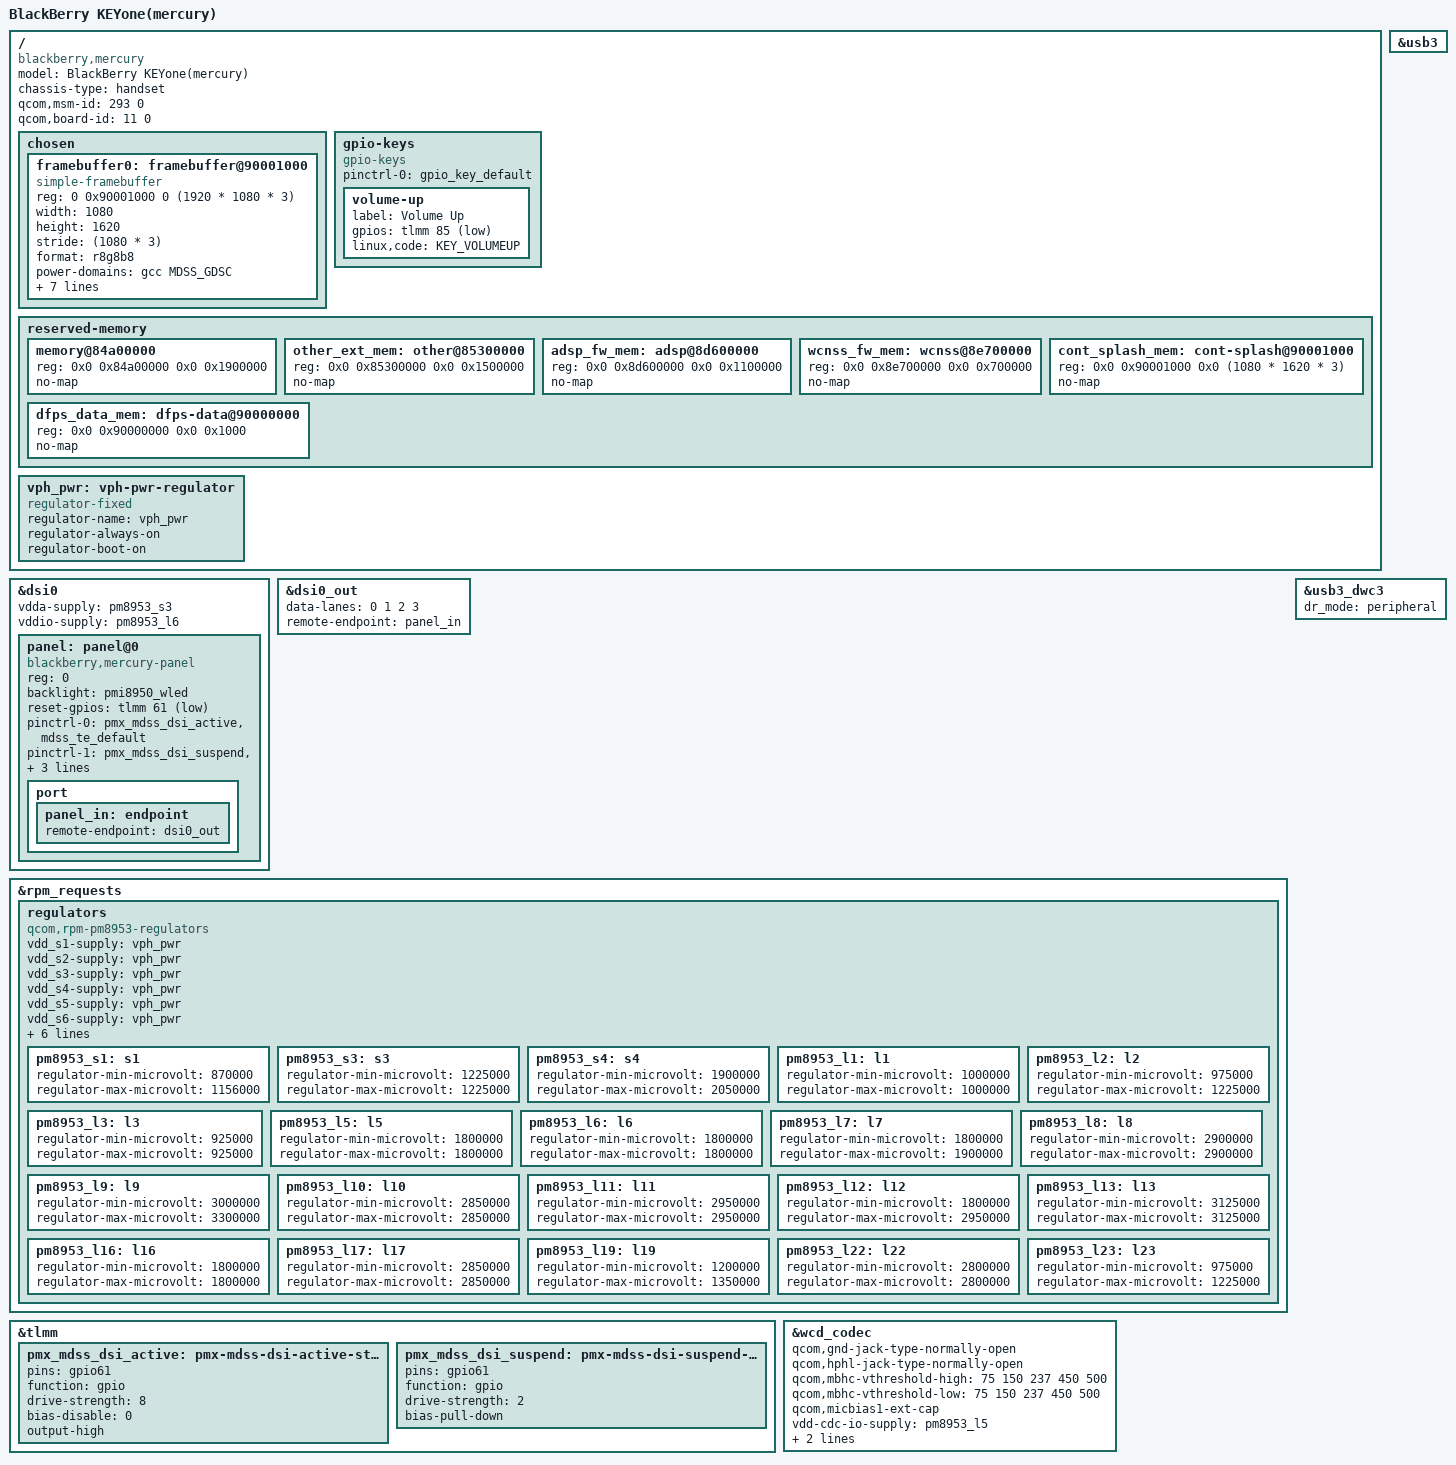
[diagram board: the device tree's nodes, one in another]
// SPDX-License-Identifier: GPL-2.0-only
/dts-v1/;

#include "msm8953.dtsi"
#include "pm8953.dtsi"
#include "pmi8950.dtsi"

#include <dt-bindings/gpio/gpio.h>
#include <dt-bindings/leds/common.h>

/delete-node/ &adsp_fw_mem;
/delete-node/ &wcnss_fw_mem;

/ {
	model = "BlackBerry KEYone(mercury)";
	compatible = "blackberry,mercury", "qcom,msm8953";
	chassis-type = "handset";
	qcom,msm-id = <293 0>;
	qcom,board-id = <11 0>;

	chosen {
		#address-cells = <2>;
		#size-cells = <2>;
		ranges;

		framebuffer0: framebuffer@90001000 {
			compatible = "simple-framebuffer";
			reg = <0 0x90001000 0 (1920 * 1080 * 3)>;

			width = <1080>;
			height = <1620>;
			stride = <(1080 * 3)>;
			format = "r8g8b8";

			power-domains = <&gcc MDSS_GDSC>;

			clocks = <&gcc GCC_MDSS_AHB_CLK>,
				 <&gcc GCC_MDSS_AXI_CLK>,
				 <&gcc GCC_MDSS_VSYNC_CLK>,
				 <&gcc GCC_MDSS_MDP_CLK>,
				 <&gcc GCC_MDSS_BYTE0_CLK>,
				 <&gcc GCC_MDSS_PCLK0_CLK>,
				 <&gcc GCC_MDSS_ESC0_CLK>;
		};
	};

	gpio-keys {
		compatible = "gpio-keys";

		pinctrl-names = "default";
		pinctrl-0 = <&gpio_key_default>;

		volume-up {
			label = "Volume Up";
			gpios = <&tlmm 85 GPIO_ACTIVE_LOW>;
			linux,code = <KEY_VOLUMEUP>;
		};
	};

	reserved-memory {
		/delete-node/memory@85b00000;

		memory@84a00000 {
			reg = <0x0 0x84a00000 0x0 0x1900000>;
			no-map;
		};

		other_ext_mem: other@85300000 {
                        reg = <0x0 0x85300000 0x0 0x1500000>;
			no-map;
                };

		adsp_fw_mem: adsp@8d600000 {
                        reg = <0x0 0x8d600000 0x0 0x1100000>;
                        no-map;
                };

		wcnss_fw_mem: wcnss@8e700000 {
                        reg = <0x0 0x8e700000 0x0 0x700000>;
                        no-map;
                };

		/delete-node/memory@90001000;
		cont_splash_mem: cont-splash@90001000 {
			reg = <0x0 0x90001000 0x0 (1080 * 1620 * 3)>;
			no-map;
		};

		dfps_data_mem: dfps-data@90000000 {
                        reg = <0x0 0x90000000 0x0 0x1000>;
			no-map;
                };

	};

	vph_pwr: vph-pwr-regulator {
		compatible = "regulator-fixed";
		regulator-name = "vph_pwr";
		regulator-always-on;
		regulator-boot-on;
	};

};

&dsi0 {
	vdda-supply = <&pm8953_s3>;
	vddio-supply = <&pm8953_l6>;

	panel: panel@0 {
		compatible = "blackberry,mercury-panel";
		reg = <0>;

		backlight = <&pmi8950_wled>;

		reset-gpios = <&tlmm 61 GPIO_ACTIVE_LOW>;

		pinctrl-names = "default", "sleep";
		pinctrl-0 = <&pmx_mdss_dsi_active &mdss_te_default>;
		pinctrl-1 = <&pmx_mdss_dsi_suspend &mdss_te_default>;

		vsp-supply = <&lab_vreg>;
		vsn-supply = <&ibb_vreg>;

		port {
			panel_in: endpoint {
				remote-endpoint = <&dsi0_out>;
			};
		};
	};
};

&dsi0_out {
	data-lanes = <0 1 2 3>;
	remote-endpoint = <&panel_in>;
};

&rpm_requests {
	regulators {
		compatible = "qcom,rpm-pm8953-regulators";
		vdd_s1-supply = <&vph_pwr>;
		vdd_s2-supply = <&vph_pwr>;
		vdd_s3-supply = <&vph_pwr>;
		vdd_s4-supply = <&vph_pwr>;
		vdd_s5-supply = <&vph_pwr>;
		vdd_s6-supply = <&vph_pwr>;
		vdd_s7-supply = <&vph_pwr>;
		vdd_l1-supply = <&pm8953_s3>;
		vdd_l2_l3-supply = <&pm8953_s3>;
		vdd_l4_l5_l6_l7_l16_l19-supply = <&pm8953_s4>;
		vdd_l8_l11_l12_l13_l14_l15-supply = <&vph_pwr>;
		vdd_l9_l10_l17_l18_l22-supply = <&vph_pwr>;

		pm8953_s1: s1 {
			regulator-min-microvolt = <870000>;
			regulator-max-microvolt = <1156000>;
		};

		pm8953_s3: s3 {
			regulator-min-microvolt = <1225000>;
			regulator-max-microvolt = <1225000>;
		};

		pm8953_s4: s4 {
			regulator-min-microvolt = <1900000>;
			regulator-max-microvolt = <2050000>;
		};

		pm8953_l1: l1 {
			regulator-min-microvolt = <1000000>;
			regulator-max-microvolt = <1000000>;
		};

		pm8953_l2: l2 {
			regulator-min-microvolt = <975000>;
			regulator-max-microvolt = <1225000>;
		};

		pm8953_l3: l3 {
			regulator-min-microvolt = <925000>;
			regulator-max-microvolt = <925000>;
		};

		pm8953_l5: l5 {
			regulator-min-microvolt = <1800000>;
			regulator-max-microvolt = <1800000>;
		};

		pm8953_l6: l6 {
			regulator-min-microvolt = <1800000>;
			regulator-max-microvolt = <1800000>;
		};

		pm8953_l7: l7 {
			regulator-min-microvolt = <1800000>;
			regulator-max-microvolt = <1900000>;
		};

		pm8953_l8: l8 {
			regulator-min-microvolt = <2900000>;
			regulator-max-microvolt = <2900000>;
		};

		pm8953_l9: l9 {
			regulator-min-microvolt = <3000000>;
			regulator-max-microvolt = <3300000>;
		};

		pm8953_l10: l10 {
			regulator-min-microvolt = <2850000>;
			regulator-max-microvolt = <2850000>;
		};

		pm8953_l11: l11 {
			regulator-min-microvolt = <2950000>;
			regulator-max-microvolt = <2950000>;
		};

		pm8953_l12: l12 {
			regulator-min-microvolt = <1800000>;
			regulator-max-microvolt = <2950000>;
		};

		pm8953_l13: l13 {
			regulator-min-microvolt = <3125000>;
			regulator-max-microvolt = <3125000>;
		};

		pm8953_l16: l16 {
			regulator-min-microvolt = <1800000>;
			regulator-max-microvolt = <1800000>;
		};

		pm8953_l17: l17 {
			regulator-min-microvolt = <2850000>;
			regulator-max-microvolt = <2850000>;
		};

		pm8953_l19: l19 {
			regulator-min-microvolt = <1200000>;
			regulator-max-microvolt = <1350000>;
		};

		pm8953_l22: l22 {
			regulator-min-microvolt = <2800000>;
			regulator-max-microvolt = <2800000>;
		};

		pm8953_l23: l23 {
			regulator-min-microvolt = <975000>;
			regulator-max-microvolt = <1225000>;
		};
	};
};

&tlmm {
	pmx_mdss_dsi_active: pmx-mdss-dsi-active-state {
		pins = "gpio61";
		function = "gpio";
		drive-strength = <8>;
		bias-disable = <0>;
		output-high;
	};

	pmx_mdss_dsi_suspend: pmx-mdss-dsi-suspend-state {
		pins = "gpio61";
		function = "gpio";
		drive-strength = <2>;
		bias-pull-down;
	};
};

&usb3 {
	status = "okay";
};

&usb3_dwc3 {
	dr_mode = "peripheral";
};

&wcd_codec {
	qcom,gnd-jack-type-normally-open;
	qcom,hphl-jack-type-normally-open;
	qcom,mbhc-vthreshold-high = <75 150 237 450 500>;
	qcom,mbhc-vthreshold-low = <75 150 237 450 500>;
	qcom,micbias1-ext-cap;

	vdd-cdc-io-supply = <&pm8953_l5>;
	vdd-cdc-tx-rx-cx-supply = <&pm8953_s4>;
	vdd-micbias-supply = <&pm8953_l13>;

	status = "okay";
};
